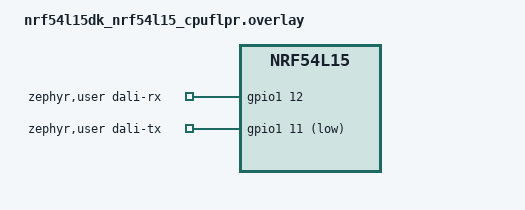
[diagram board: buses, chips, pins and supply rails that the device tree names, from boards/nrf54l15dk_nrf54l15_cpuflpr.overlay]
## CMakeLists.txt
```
# SPDX-License-Identifier: Apache-2.0
# SPDX-FileCopyrightText: Copyright (c) 2026 N-iX

cmake_minimum_required(VERSION 3.20.0)

find_package(Zephyr REQUIRED HINTS $ENV{ZEPHYR_BASE})
project(dali_nrf54_flpr C)

set(DALI_FLPR_ENGINE_LIB_DIR
    ${CMAKE_CURRENT_LIST_DIR}/../zephyr/blobs/cpuflpr/lib/nrf54l15)
set(DALI_FLPR_ENGINE_LIB_RELEASE
    ${DALI_FLPR_ENGINE_LIB_DIR}/libdali_flpr_engine_release.a)
set(DALI_FLPR_ENGINE_LIB_DEBUG
    ${DALI_FLPR_ENGINE_LIB_DIR}/libdali_flpr_engine_debug.a)

if(CONFIG_DALI_FLPR_LOG_DEBUG)
  set(DALI_FLPR_ENGINE_LIB ${DALI_FLPR_ENGINE_LIB_DEBUG})
else()
  set(DALI_FLPR_ENGINE_LIB ${DALI_FLPR_ENGINE_LIB_RELEASE})
endif()

if(NOT EXISTS ${DALI_FLPR_ENGINE_LIB})
  message(FATAL_ERROR
    "Missing FLPR DALI engine archive: ${DALI_FLPR_ENGINE_LIB}\n"
    "Fetch module blobs with: west blobs fetch dali-nrf54")
endif()

add_library(dali_flpr_engine STATIC IMPORTED GLOBAL)
set_target_properties(dali_flpr_engine PROPERTIES
  IMPORTED_LOCATION ${DALI_FLPR_ENGINE_LIB}
)

target_include_directories(app PRIVATE
  ${CMAKE_CURRENT_LIST_DIR}/../include
  ${CMAKE_CURRENT_LIST_DIR}/src
)

target_link_libraries(app PRIVATE dali_flpr_engine)

target_sources(app PRIVATE
  src/dali_heartbeat.c
  src/dali_ipc_server.c
  src/main.c
)

target_sources_ifdef(CONFIG_DALI_FLPR_CPU_LOAD_REPORTING app PRIVATE
  src/cpu_load_reporter.c
)
```

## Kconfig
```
mainmenu "DALI nRF54 FLPR runtime"

source "Kconfig.zephyr"

rsource "Kconfig.flpr"
```

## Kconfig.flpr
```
# SPDX-License-Identifier: Apache-2.0
# SPDX-FileCopyrightText: Copyright (c) 2026 N-iX

choice DALI_FLPR_LOG_LEVEL_CHOICE
	prompt "FLPR DALI log level"
	default DALI_FLPR_LOG_INFO
	help
	  Select the Zephyr log level used by the FLPR-side DALI runtime.
	  This controls the amount of diagnostic output emitted by the
	  CPUFLPR image for the DALI engine and its runtime shell.

	  Use the info level for normal development and the debug level
	  when tracing discovery, control, or IPC behavior.

config DALI_FLPR_LOG_INFO
	bool "Info"
	help
	  Enable informational, warning, and error logging for the FLPR
	  DALI runtime.

	  This is the default setting for normal application use when the
	  extra detail from debug logs is not needed.

config DALI_FLPR_LOG_DEBUG
	bool "Debug"
	help
	  Enable debug, informational, warning, and error logging for the
	  FLPR DALI runtime.

	  Use this level when tracing the internal sequencing of the FLPR
	  DALI engine during integration or hardware bring-up.

endchoice

config DALI_FLPR_LOG_LEVEL
	int
	default 3 if DALI_FLPR_LOG_INFO
	default 4 if DALI_FLPR_LOG_DEBUG
	help
	  Internal numeric log level used by LOG_MODULE_REGISTER() for FLPR
	  DALI modules.

config DALI_FLPR_CPU_LOAD_REPORTING
	bool "Periodic CPU load reporting"
	depends on CPU_LOAD
	help
	  Report the CPUFLPR non-idle time periodically. This diagnostic option
	  is enabled through the DALI_CPU_LOAD_MEASUREMENT sysbuild option. It
	  reports total core activity, including interrupt handling, but does
	  not attribute load to individual threads or DALI operations.

config DALI_FLPR_CPU_LOAD_REPORT_INTERVAL_S
	int "CPU load report interval in seconds"
	depends on DALI_FLPR_CPU_LOAD_REPORTING
	range 1 3600
	default 10
	help
	  Time window used to calculate and report CPUFLPR load.

config DALI_FLPR_IPC_LATENCY_MEASUREMENT
	bool "IPC latency GPIO marker"
	depends on GPIO
	help
	  Drive LED3 high when CPUFLPR receives a CPUAPP DALI IPC request and
	  return it low immediately before sending the response. This diagnostic
	  option is enabled through the DALI_IPC_LATENCY_MEASUREMENT sysbuild
	  option.
```

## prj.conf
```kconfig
CONFIG_GPIO=y
CONFIG_CONSOLE=y
CONFIG_PRINTK=y
CONFIG_SERIAL=y
CONFIG_UART_CONSOLE=y
CONFIG_CLOCK_CONTROL=n
CONFIG_LOG=y
CONFIG_LOG_MAX_LEVEL=4
CONFIG_LOG_DEFAULT_LEVEL=3
CONFIG_LOG_MODE_IMMEDIATE=y
CONFIG_BOOT_BANNER=n
CONFIG_NCS_BOOT_BANNER=n
CONFIG_DALI_FLPR_LOG_INFO=y
CONFIG_DALI_FLPR_LOG_DEBUG=n
```

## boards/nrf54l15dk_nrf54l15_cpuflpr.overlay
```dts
// SPDX-License-Identifier: Apache-2.0

/ {
	zephyr,user {
		dali-rx-gpios = <&gpio1 12 GPIO_ACTIVE_HIGH>;
		dali-tx-gpios = <&gpio1 11 GPIO_ACTIVE_LOW>;
	};
};
```

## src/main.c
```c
// SPDX-License-Identifier: Apache-2.0
// SPDX-FileCopyrightText: Copyright (c) 2026 N-iX

#include <zephyr/kernel.h>
#include <zephyr/logging/log.h>

#include <dali/dali_api.h>

#if defined(CONFIG_DALI_FLPR_CPU_LOAD_REPORTING)
#include "cpu_load_reporter.h"
#endif
#include "dali_services_flpr.h"

LOG_MODULE_REGISTER(dali_flpr_main, CONFIG_DALI_FLPR_LOG_LEVEL);

int main(void)
{
	int err;

	LOG_INF("CPUFLPR runtime started");

	err = dali_heartbeat_init();
	if (err != 0) {
		LOG_ERR("heartbeat init failed -> %d", err);
		return err;
	}

	err = dali_api_init();
	if (err != 0) {
		LOG_ERR("dali_api_init failed -> %d", err);
		return err;
	}

	err = dali_ipc_server_init();
	if (err != 0) {
		LOG_ERR("ipc server init failed -> %d", err);
		return err;
	}

	LOG_INF("IPC runtime ready");
#if defined(CONFIG_DALI_FLPR_CPU_LOAD_REPORTING)
	dali_cpu_load_reporter_start();
#endif
	while (true) {
		k_sleep(K_FOREVER);
	}
}
```

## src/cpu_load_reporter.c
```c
// SPDX-License-Identifier: Apache-2.0
// SPDX-FileCopyrightText: Copyright (c) 2026 N-iX

#include <zephyr/debug/cpu_load.h>
#include <zephyr/kernel.h>
#include <zephyr/logging/log.h>

#include "cpu_load_reporter.h"

LOG_MODULE_REGISTER(dali_flpr_cpu_load, CONFIG_DALI_FLPR_LOG_LEVEL);

static void dali_cpu_load_report(struct k_work *work);

K_WORK_DELAYABLE_DEFINE(dali_cpu_load_work, dali_cpu_load_report);

void dali_cpu_load_reporter_reset(void)
{
	(void)cpu_load_get(true);
}

void dali_cpu_load_reporter_report(const char *window)
{
	int load_per_mille = cpu_load_get(true);

	if (load_per_mille < 0) {
		LOG_ERR("core=cpuflpr load read failed rc=%d", load_per_mille);
	} else {
		LOG_INF("core=cpuflpr load=%d.%d%% window=%s",
			load_per_mille / 10, load_per_mille % 10, window);
	}
}

static void dali_cpu_load_report(struct k_work *work)
{
	ARG_UNUSED(work);

	dali_cpu_load_reporter_report("periodic");

	(void)k_work_reschedule(
		&dali_cpu_load_work,
		K_SECONDS(CONFIG_DALI_FLPR_CPU_LOAD_REPORT_INTERVAL_S));
}

void dali_cpu_load_reporter_start(void)
{
	dali_cpu_load_reporter_reset();
	(void)k_work_reschedule(
		&dali_cpu_load_work,
		K_SECONDS(CONFIG_DALI_FLPR_CPU_LOAD_REPORT_INTERVAL_S));
}
```

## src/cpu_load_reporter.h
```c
/* SPDX-License-Identifier: Apache-2.0 */
/* SPDX-FileCopyrightText: Copyright (c) 2026 N-iX */

#ifndef DALI_FLPR_CPU_LOAD_REPORTER_H_
#define DALI_FLPR_CPU_LOAD_REPORTER_H_

void dali_cpu_load_reporter_start(void);
void dali_cpu_load_reporter_reset(void);
void dali_cpu_load_reporter_report(const char *window);

#endif /* DALI_FLPR_CPU_LOAD_REPORTER_H_ */
```

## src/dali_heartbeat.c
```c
// SPDX-License-Identifier: Apache-2.0

#include <errno.h>
#include <stdbool.h>
#include <zephyr/devicetree.h>
#include <zephyr/drivers/gpio.h>
#include <zephyr/kernel.h>
#include <zephyr/logging/log.h>

LOG_MODULE_REGISTER(dali_heartbeat, CONFIG_DALI_FLPR_LOG_LEVEL);

#define DALI_HEARTBEAT_MS   500U
#define DALI_HEARTBEAT_NODE DT_ALIAS(led1)

#if !DT_NODE_HAS_STATUS_OKAY(DALI_HEARTBEAT_NODE)
#error "Unsupported board: led1 devicetree alias is not defined"
#endif

static const struct gpio_dt_spec dali_heartbeat_led =
	GPIO_DT_SPEC_GET(DALI_HEARTBEAT_NODE, gpios);

K_THREAD_STACK_DEFINE(dali_heartbeat_stack, 512);
static struct k_thread dali_heartbeat_thread;
static bool dali_heartbeat_started;

static void dali_heartbeat_thread_fn(void *arg1, void *arg2, void *arg3)
{
	int err;
	bool state = false;

	ARG_UNUSED(arg1);
	ARG_UNUSED(arg2);
	ARG_UNUSED(arg3);

	while (true) {
		state = !state;
		err = gpio_pin_set_dt(&dali_heartbeat_led, state);
		if (err != 0) {
			LOG_ERR("LED1 set failed -> %d", err);
			return;
		}

		k_sleep(K_MSEC(DALI_HEARTBEAT_MS));
	}
}

int dali_heartbeat_init(void)
{
	int err;

	if (dali_heartbeat_started) {
		return 0;
	}

	if (!gpio_is_ready_dt(&dali_heartbeat_led)) {
		return -ENODEV;
	}

	err = gpio_pin_configure_dt(&dali_heartbeat_led, GPIO_OUTPUT_INACTIVE);
	if (err != 0) {
		return err;
	}

	(void)k_thread_create(&dali_heartbeat_thread, dali_heartbeat_stack,
			      K_THREAD_STACK_SIZEOF(dali_heartbeat_stack),
			      dali_heartbeat_thread_fn, NULL, NULL, NULL, 7, 0,
			      K_NO_WAIT);

	dali_heartbeat_started = true;
	return 0;
}
```

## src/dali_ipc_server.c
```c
// SPDX-License-Identifier: Apache-2.0
// SPDX-FileCopyrightText: Copyright (c) 2026 N-iX

#include <errno.h>
#include <string.h>

#include <zephyr/device.h>
#include <zephyr/drivers/gpio.h>
#include <zephyr/ipc/ipc_service.h>
#include <zephyr/kernel.h>
#include <zephyr/logging/log.h>

#include <dali/dali_api.h>
#include <dali/dali_ipc_protocol.h>

#if defined(CONFIG_DALI_FLPR_CPU_LOAD_REPORTING)
#include "cpu_load_reporter.h"
#endif

LOG_MODULE_REGISTER(dali_ipc_server, CONFIG_DALI_FLPR_LOG_LEVEL);

static const struct device *const dali_ipc_instance =
	DEVICE_DT_GET(DT_NODELABEL(ipc0));
static struct ipc_ept dali_ipc_endpoint;
static K_SEM_DEFINE(dali_ipc_bound_sem, 0, 1);
static struct k_work dali_ipc_request_work;
static struct dali_ipc_message dali_ipc_pending_request;
static bool dali_ipc_server_ready;
static bool dali_ipc_request_valid;

#if defined(CONFIG_DALI_FLPR_IPC_LATENCY_MEASUREMENT)
#define DALI_IPC_LATENCY_NODE DT_ALIAS(led3)

static const struct gpio_dt_spec dali_ipc_latency_gpio =
	GPIO_DT_SPEC_GET(DALI_IPC_LATENCY_NODE, gpios);

static int dali_ipc_latency_init(void)
{
	if (!gpio_is_ready_dt(&dali_ipc_latency_gpio)) {
		return -ENODEV;
	}

	return gpio_pin_configure_dt(&dali_ipc_latency_gpio,
				     GPIO_OUTPUT_INACTIVE);
}

static void dali_ipc_latency_start(void)
{
	(void)gpio_pin_set_dt(&dali_ipc_latency_gpio, 1);
}

static void dali_ipc_latency_stop(void)
{
	(void)gpio_pin_set_dt(&dali_ipc_latency_gpio, 0);
}
#else
static int dali_ipc_latency_init(void)
{
	return 0;
}

static void dali_ipc_latency_start(void)
{
}

static void dali_ipc_latency_stop(void)
{
}
#endif

#if defined(CONFIG_DALI_FLPR_CPU_LOAD_REPORTING)
static const char *dali_ipc_opcode_name(uint8_t opcode)
{
	switch (opcode) {
	case DALI_IPC_OPCODE_INIT:
		return "init";
	case DALI_IPC_OPCODE_DISCOVER:
		return "discover";
	case DALI_IPC_OPCODE_OFF_SHORT:
		return "off_short";
	case DALI_IPC_OPCODE_RECALL_MAX_SHORT:
		return "recall_max_short";
	case DALI_IPC_OPCODE_SET_LEVEL_SHORT:
		return "set_level_short";
	case DALI_IPC_OPCODE_QUERY_STATUS_SHORT:
		return "query_status_short";
	case DALI_IPC_OPCODE_QUERY_ACTUAL_LEVEL_SHORT:
		return "query_actual_level_short";
	case DALI_IPC_OPCODE_OFF_BROADCAST:
		return "off_broadcast";
	case DALI_IPC_OPCODE_RECALL_MAX_BROADCAST:
		return "recall_max_broadcast";
	case DALI_IPC_OPCODE_SET_LEVEL_BROADCAST:
		return "set_level_broadcast";
	default:
		return "unknown";
	}
}
#endif

static void dali_ipc_server_bound(void *priv)
{
	ARG_UNUSED(priv);

	k_sem_give(&dali_ipc_bound_sem);
}

static int
dali_ipc_server_send_response(const struct dali_ipc_message *response)
{
	if (response == NULL) {
		return -EINVAL;
	}

	dali_ipc_latency_stop();
	return ipc_service_send(&dali_ipc_endpoint, response,
				sizeof(*response));
}

static void dali_ipc_server_process(struct k_work *work)
{
	struct dali_ipc_message request;
	struct dali_ipc_message response;
	int err = 0;

	ARG_UNUSED(work);

	if (!dali_ipc_request_valid) {
		return;
	}

	memcpy(&request, &dali_ipc_pending_request, sizeof(request));
	dali_ipc_request_valid = false;

	memset(&response, 0, sizeof(response));
	response.version = DALI_IPC_PROTOCOL_VERSION;
	response.type = DALI_IPC_MESSAGE_TYPE_RESPONSE;
	response.opcode = request.opcode;
	response.sequence = request.sequence;

#if defined(CONFIG_DALI_FLPR_CPU_LOAD_REPORTING)
	dali_cpu_load_reporter_reset();
#endif

	switch (request.opcode) {
	case DALI_IPC_OPCODE_INIT:
		err = dali_api_init();
		break;
	case DALI_IPC_OPCODE_DISCOVER:
		err = dali_api_discover(&response.discovery);
		break;
	case DALI_IPC_OPCODE_OFF_SHORT:
		err = dali_api_off_short(request.short_address);
		break;
	case DALI_IPC_OPCODE_RECALL_MAX_SHORT:
		err = dali_api_recall_max_short(request.short_address);
		break;
	case DALI_IPC_OPCODE_SET_LEVEL_SHORT:
		err = dali_api_set_level_short(request.short_address,
					       request.value);
		break;
	case DALI_IPC_OPCODE_QUERY_STATUS_SHORT:
		err = dali_api_query_status_short(request.short_address,
						  &response.value);
		break;
	case DALI_IPC_OPCODE_QUERY_ACTUAL_LEVEL_SHORT:
		err = dali_api_query_actual_level_short(request.short_address,
							&response.value);
		break;
	case DALI_IPC_OPCODE_OFF_BROADCAST:
		err = dali_api_off_broadcast();
		break;
	case DALI_IPC_OPCODE_RECALL_MAX_BROADCAST:
		err = dali_api_recall_max_broadcast();
		break;
	case DALI_IPC_OPCODE_SET_LEVEL_BROADCAST:
		err = dali_api_set_level_broadcast(request.value);
		break;
	default:
		err = -EINVAL;
		break;
	}

#if defined(CONFIG_DALI_FLPR_CPU_LOAD_REPORTING)
	dali_cpu_load_reporter_report(dali_ipc_opcode_name(request.opcode));
#endif

	response.rc = err;
	err = dali_ipc_server_send_response(&response);
	if (err < 0) {
		LOG_ERR("failed to send response -> %d", err);
	}
}

static void dali_ipc_server_received(const void *data, size_t len, void *priv)
{
	const struct dali_ipc_message *msg = data;
	struct dali_ipc_message response;

	ARG_UNUSED(priv);

	if ((data == NULL) || (len != sizeof(*msg))) {
		return;
	}

	if ((msg->version != DALI_IPC_PROTOCOL_VERSION) ||
	    (msg->type != DALI_IPC_MESSAGE_TYPE_REQUEST)) {
		return;
	}

	if (dali_ipc_request_valid) {
		memset(&response, 0, sizeof(response));
		response.version = DALI_IPC_PROTOCOL_VERSION;
		response.type = DALI_IPC_MESSAGE_TYPE_RESPONSE;
		response.opcode = msg->opcode;
		response.sequence = msg->sequence;
		response.rc = -EBUSY;
		(void)dali_ipc_server_send_response(&response);
		return;
	}

	dali_ipc_latency_start();
	memcpy(&dali_ipc_pending_request, msg,
	       sizeof(dali_ipc_pending_request));
	dali_ipc_request_valid = true;
	k_work_submit(&dali_ipc_request_work);
}

static struct ipc_ept_cfg dali_ipc_ep_cfg = {
	.name = "dali_api",
};

int dali_ipc_server_init(void)
{
	int err;

	if (dali_ipc_server_ready) {
		return 0;
	}

	if (!device_is_ready(dali_ipc_instance)) {
		return -ENODEV;
	}

	err = dali_ipc_latency_init();
	if (err != 0) {
		return err;
	}

	dali_ipc_ep_cfg.cb.bound = dali_ipc_server_bound;
	dali_ipc_ep_cfg.cb.received = dali_ipc_server_received;
	k_work_init(&dali_ipc_request_work, dali_ipc_server_process);

	err = ipc_service_open_instance(dali_ipc_instance);
	if ((err < 0) && (err != -EALREADY)) {
		return err;
	}

	err = ipc_service_register_endpoint(
		dali_ipc_instance, &dali_ipc_endpoint, &dali_ipc_ep_cfg);
	if ((err < 0) && (err != -EALREADY)) {
		return err;
	}

	err = k_sem_take(&dali_ipc_bound_sem, K_SECONDS(5));
	if (err != 0) {
		return err;
	}

	dali_ipc_server_ready = true;
	LOG_INF("IPC server ready");
	return 0;
}
```

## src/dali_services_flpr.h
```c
/* SPDX-License-Identifier: Apache-2.0 */

#ifndef DALI_SERVICES_FLPR_H_
#define DALI_SERVICES_FLPR_H_

int dali_heartbeat_init(void);
int dali_ipc_server_init(void);

#endif /* DALI_SERVICES_FLPR_H_ */
```
